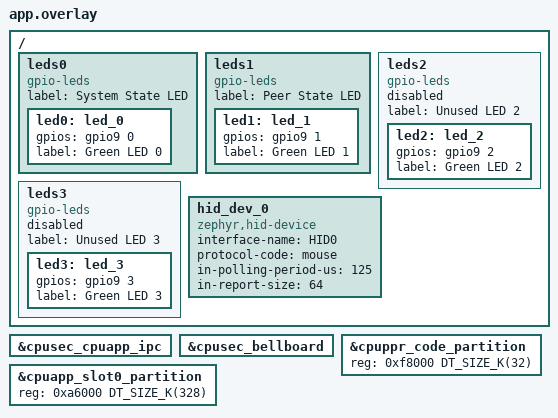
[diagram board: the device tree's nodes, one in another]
/*
 * Copyright (c) 2024 Nordic Semiconductor ASA
 *
 * SPDX-License-Identifier: LicenseRef-Nordic-5-Clause
 */

/ {
	/* Redefine leds to fit CAF requirements. */
	/delete-node/ leds;

	leds0 {
		compatible = "gpio-leds";
		status = "okay";
		label = "System State LED";

		led0: led_0 {
			gpios = < &gpio9 0 GPIO_ACTIVE_HIGH >;
			label = "Green LED 0";
		};
	};

	leds1 {
		compatible = "gpio-leds";
		status = "okay";
		label = "Peer State LED";

		led1: led_1 {
			gpios = < &gpio9 1 GPIO_ACTIVE_HIGH >;
			label = "Green LED 1";
		};
	};

	leds2 {
		compatible = "gpio-leds";
		status = "disabled";
		label = "Unused LED 2";

		led2: led_2 {
			gpios = < &gpio9 2 GPIO_ACTIVE_HIGH >;
			label = "Green LED 2";
		};
	};

	leds3 {
		compatible = "gpio-leds";
		status = "disabled";
		label = "Unused LED 3";

		led3: led_3 {
			gpios = < &gpio9 3 GPIO_ACTIVE_HIGH >;
			label = "Green LED 3";
		};
	};

	hid_dev_0: hid_dev_0 {
		compatible = "zephyr,hid-device";
		interface-name = "HID0";
		protocol-code = "mouse";
		in-polling-period-us = <125>;
		in-report-size = <64>;
	};
};

&cpusec_cpuapp_ipc {
	status = "okay";
};

&cpusec_bellboard {
	status = "okay";
};

/* Shrink ppr partition as ppr core is not used and extend app core code partition. */
&cpuppr_code_partition {
	reg = < 0xf8000 DT_SIZE_K(32) >;
};

&cpuapp_slot0_partition {
	reg = < 0xa6000 DT_SIZE_K(328) >;
};
